# LPC11Axx register map
File version: 0.6
CPU: CM0 r0p0, little endian, no MPU, no FPU, 2 interrupt priority bits
Registers are 32-bit, read-write, reset 0x0 unless marked. A register's access mark holds for its fields unless they carry their own. Offsets are from the block's base; [hi:lo] are bit positions; {n}, {i} and the like mark numbered series.

## ADC
Base 0x4001C000
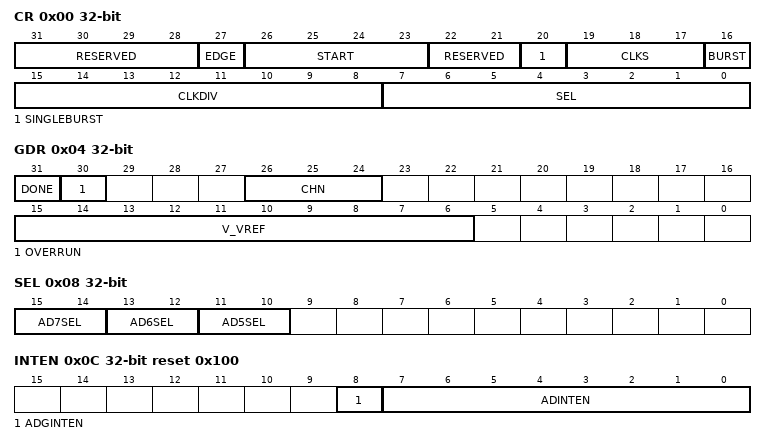
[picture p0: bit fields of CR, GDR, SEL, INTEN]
0x00 CR — A/D Control Register. The CR register must be written to select the operating mode before A/D conversion can occur.
  [31:28] RESERVED — Reserved, user software should not write ones to reserved bits. The value read from a reserved bit is not defined.
  [27] EDGE — This bit is significant only when the START field contains 0100-1110. In these cases:
    0=START_CONVERSION_ON_ (Start conversion on a rising edge on the selected signal.); 1=START_CONVERSION_ON_ (Start conversion on a falling edge on the selected signal.)
  [26:23] START — When the BURST bit is 0, these bits control whether/when an A/D conversion is started. All other values are reserved.
    0=NO_START_THIS_VALUE (No start (this value should be used when clearing PDN to 0).); 2=START_CONVERSION_NOW; 4=START_CONVERSION_WHE (Start conversion when the edge selected by bit 27 occurs on ATRG0.); 5=START_CONVERSION_WHE (Start conversion when the edge selected by bit 27 occurs on the analog comparator output.); 6=START_CONVERSION_WHE (Start conversion when the edge selected by bit 27 occurs on ATRG1.); 8=START_CONVERSION_WHE (Start conversion when the edge selected by bit 27 occurs on CT32B0_MAT0[1].); 10=START_CONVERSION_WHE (Start conversion when the edge selected by bit 27 occurs on CT32B0_MAT1[1].); 12=START_CONVERSION_WHE (Start conversion when the edge selected by bit 27 occurs on CT16B0_MAT0[1].); 14=START_CONVERSION_WHE (Start conversion when the edge selected by bit 27 occurs on CT16B0_MAT1[1].)
  [22:21] RESERVED — Reserved, user software should not write ones to reserved bits. The value read from a reserved bit is not defined.
  [20] SINGLEBURST — Single-burst mode
    0=CONTINUOUS_BURST (Continuous. Burst mode can only be terminated via a software write to clear bit 16 in this register.); 1=SINGLE_BURST (Single-burst. When the burst mode is selected by writing a 1 to bit 16 in this register, the ADC cycles through a single set of conversions on the selection of channels specified in the SEL field. Once the conversion has been completed on each selected channel, bit 16 is automatically cleared and the conversions stop until a new trigger event occurs.)
  [19:17] CLKS — This field selects the number of clocks used for each conversion in Burst mode, and the number of bits of accuracy of the result in the LS bits of ADDR, between 11 clocks (10 bits) and 4 clocks (3 bits).
    0=11_CLOCKS (11 clocks / 10 bits); 1=10_CLOCKS (10 clocks / 9 bits); 2=9_CLOCKS (9 clocks / 8 bits); 3=8_CLOCKS (8 clocks / 7 bits); 4=7_CLOCKS (7 clocks / 6 bits); 5=6_CLOCK (6 clocks / 5 bits); 6=5_CLOCKS (5 clocks / 4 bits); 7=4_CLOCKS (4 clocks / 3 bits)
  [16] BURST — Burst mode
    0=SOFTWARE_CONTROLLED_ (Software-controlled mode: Conversions are software-controlled and require 11 clocks.); 1=HARDWARE_SCAN_MODE_ (Hardware scan mode: The AD converter does repeated conversions at the rate selected by the CLKS field, scanning (if necessary) through the pins selected by 1s in the SEL field. The first conversion after the start corresponds to the least-significant bit set to 1 in the SEL field, then the next higher bits (pins) set to 1 are scanned if applicable. Repeated conversions can be terminated by clearing this bit, but the conversion in progress when this bit is cleared will be completed. If bit 20 in this register is set (single-burst mode), hardware clears this bit automatically after one set of conversions on all of the selected channels.)
  [15:8] CLKDIV — The APB clock (PCLK) is divided by CLKDIV +1 to produce the clock for the ADC, which should be less than or equal to 4.5 MHz. Typically, software should program the smallest value in this field that yields a clock of 4.5 MHz or slightly less, but in certain cases (such as a high-impedance analog source) a slower clock may be desirable.
  [7:0] SEL — Selects which of the AD7:0 pins is (are) to be sampled and converted. Bit 0 selects Pin AD0, bit 1 selects pin AD1,..., and bit 7 selects pin AD7. In software-controlled mode (BURST = 0), only one channel can be selected, i.e. only one of these bits should be 1. In hardware scan mode (BURST = 1), any numbers of channels can be selected, i.e any or all bits can be set to 1. If all bits are 0 (as after Reset) channel 0 is selected automatically.
0x04 GDR ro reset not defined — A/D Global Data Register. Contains the result of the most recent A/D conversion.
  [31] DONE — This bit is set to 1 when an A/D conversion completes. It is cleared when this register is read and when the ADCR is written. If the ADCR is written while a conversion is still in progress, this bit is set and a new conversion is started.
  [30] OVERRUN — This bit is 1 in burst mode if the results of one or more conversions was (were) lost and overwritten before the conversion that produced the result in the LS bits. In non-FIFO operation, this bit is cleared by reading this register.
  [26:24] CHN — These bits contain the channel from which the LS bits were converted.
  [15:6] V_VREF — When DONE is 1, this field contains a binary fraction representing the voltage on the ADn pin selected by the SEL field, divided by the voltage on the VDD pin. Zero in the field indicates that the voltage on the ADn pin was less than, equal to, or close to that on VSS, while 0x3FF indicates that the voltage on ADn was close to, equal to, or greater than that on VREF.
0x08 SEL — A/D Select Register. Selects between external pins and internal sources.
  [15:14] AD7SEL — This field selects the source signal for channel 7.
    0=AD7_PIN; 1=NO_CONNECTION_OR_LOA (No connection or load); 2=TEMPERATURE_SENSOR; 3=RESERVED_DO_NOT_PRO (Reserved. Do not program this value.)
  [13:12] AD6SEL — This field selects the source signal for channel 6.
    0=AD6_PIN; 1=NO_CONNECTION_OR_LOA (No connection or load); 2=INTERNAL_VOLTAGE_REF (Internal voltage reference); 3=RESERVED_DO_NOT_PRO (Reserved. Do not program this value.)
  [11:10] AD5SEL — This field selects the source signal for channel 5.
    0=AD5_PIN; 1=NO_CONNECTION_OR_LOA (No connection or load); 2=CORE_VOLTAGE_REGULAT (Core voltage regulator output (1.2 to 1.8V)); 3=RESERVED_DO_NOT_PRO (Reserved. Do not program this value.)
0x0C INTEN reset 0x100 — A/D Interrupt Enable Register. This register contains enable bits that allow the DONE flag of each A/D channel to be included or excluded from contributing to the generation of an A/D interrupt.
  [8] ADGINTEN — When 1, enables the global DONE flag in ADDR to generate an interrupt. When 0, only the individual A/D channels enabled by ADINTEN 7:0 will generate interrupts.
  [7:0] ADINTEN — These bits allow control over which A/D channels generate interrupts for conversion completion. When bit 0 is one, completion of a conversion on A/D channel 0 will generate an interrupt, when bit 1 is one, completion of a conversion on A/D channel 1 will generate an interrupt, etc.
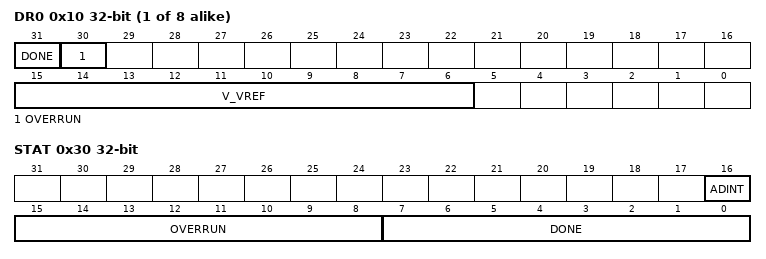
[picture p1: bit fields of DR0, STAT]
{0x10+4i} DR{i} (i=0..7) ro reset not defined — A/D Channel 0 Data Register. This register contains the result of the most recent conversion completed on channel 0
  [31] DONE — This bit is set to 1 when an A/D conversion completes. It is cleared when this register is read.
  [30] OVERRUN — This bit is 1 in burst mode if the results of one or more conversions was (were) lost and overwritten before the conversion that produced the result in the LS bits.This bit is cleared by reading this register.
  [15:6] V_VREF — When DONE is 1, this field contains a binary fraction representing the voltage on the ADn pin, divided by the voltage on the VREF pin. Zero in the field indicates that the voltage on the ADn pin was less than, equal to, or close to that on VREF, while 0x3FF indicates that the voltage on AD input was close to, equal to, or greater than that on VREF.
0x30 STAT ro — A/D Status Register. This register contains DONE and OVERRUN flags for all of the A/D channels, as well as the A/D interrupt flag.
  [16] ADINT — This bit is the A/D interrupt flag. It is one when any of the individual A/D channel Done flags is asserted and enabled to contribute to the A/D interrupt via the ADINTEN register.
  [15:8] OVERRUN — These bits mirror the OVERRUN status flags that appear in the result register for each A/D channel. Reading ADSTAT allows checking the status of all A/D channels simultaneously.
  [7:0] DONE — These bits mirror the DONE status flags that appear in the result register for each A/D channel.
